# PIC32MK1024GPK100 device description
Architecture: MIPS; Family: PIC32MK; Series: PIC32MK
Registers are 32-bit, read-write, no defined reset value unless marked. A register's access mark holds for its fields unless they carry their own. Offsets are from the block's base; [hi:lo] are bit positions; {n}, {i} and the like mark numbered series; 'fields as' and 'values as' point back to an identical list.

## USB
Instances: USB 0x1f889040 in periph_pb5_std
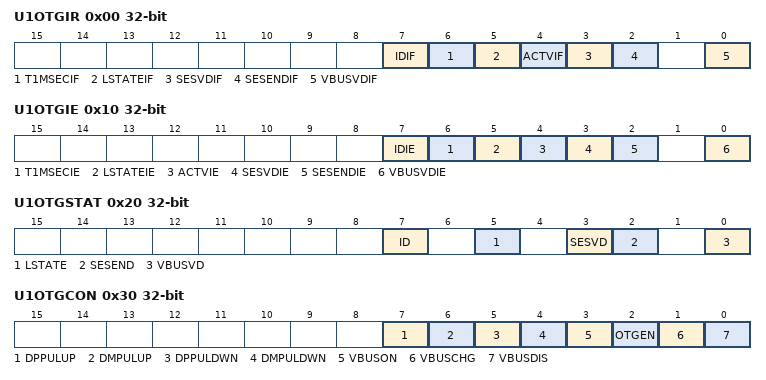
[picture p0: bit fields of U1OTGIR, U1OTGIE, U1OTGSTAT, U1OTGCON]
0x00 U1OTGIR — USB OTG Interrupt Status Register (x = 1 and 2)
  [7] IDIF — ID State Change Indicator bit
    1=Change in ID state is detected; 0=No change in ID state is detected
  [6] T1MSECIF — 1 Millisecond Timer bit
    1=1 millisecond timer has expired; 0=1 millisecond timer has not expired
  [5] LSTATEIF — Line State Stable Indicator bit
    1=USB line state has been stable for 1 millisecond; 0=USB line state has not been stable for 1 millisecond
  [4] ACTVIF — Bus Activity Indicator bit
    1=Activity on the D+, D-, ID or VBUS pins has caused the device to wake-up; 0=Activity has not been detected
  [3] SESVDIF — Session Valid Change Indicator bit
    1=Vbus voltage has dropped below the session end level; 0=Vbus voltage has not dropped below the session end level
  [2] SESENDIF — B-Device VBUS Change Indicator bit
    1=A change on the session end input was detected; 0=No change on the session end input was detected
  [0] VBUSVDIF — A-Device VBUS Change Indicator bit
    1=Change on the session valid input is detected; 0=No change on the session valid input is detected
0x10 U1OTGIE — USB OTG Interrupt Enable Register (x = 1 and 2)
  [7] IDIE — ID Interrupt Enable bit
    1=ID interrupt is enabled; 0=ID interrupt is disabled
  [6] T1MSECIE — 1 Millisecond Timer Interrupt Enable bit
    1=1 millisecond timer interrupt is enabled; 0=1 millisecond timer interrupt is disabled
  [5] LSTATEIE — Line State Interrupt Enable bit
    1=Line state interrupt is enabled; 0=Line state interrupt is disabled
  [4] ACTVIE — Bus Activity Interrupt Enable bit
    1=ACTIVITY interrupt is enabled; 0=ACTIVITY interrupt is disabled
  [3] SESVDIE — Session Valid Interrupt Enable bit
    1=Session valid interrupt is enabled; 0=Session valid interrupt is disabled
  [2] SESENDIE — B-Session End Interrupt Enable bit
    1=B-session end interrupt is enabled; 0=B-session end interrupt is disabled
  [0] VBUSVDIE — A- Vbus Valid Interrupt Enable bit
    1=A-Vbus valid interrupt is enabled; 0=A-Vbus valid interrupt is disabled
0x20 U1OTGSTAT — USB OTG Status Register (x = 1 and 2)
  [7] ID — ID Pin State Indicator bit
    1=No cable is attached or a Type-B cable has been plugged into the USB receptacle; 0=A Type-A cable has been plugged into the USB receptacle
  [5] LSTATE — Line State Stable Indicator bit
    1=USB line state (SE0 (UxCON) and JSTATE) has been stable for the previous 1 ms; 0=USB line state (SE0 and JSTATE) has not been stable for the previous 1 ms
  [3] SESVD — Session Valid Indicator bit
    1=Vbus voltage is above Session Valid on the A or B device; 0=Vbus voltage is below Session Valid on the A or B device
  [2] SESEND — B-Device Session End Indicator bit
    1=Vbus voltage is below Session Valid on the B device; 0=Vbus voltage is above Session Valid on the B device
  [0] VBUSVD — A-Device Vbus Valid Indicator bit
    1=Vbus voltage is above Session Valid on the A device; 0=Vbus voltage is below Session Valid on the A device
0x30 U1OTGCON — USB OTG Control Register (x = 1 and 2)
  [7] DPPULUP — D+ Pull-Up Enable bit
    1=D+ data line pull-up resistor is enabled; 0=D+ data line pull-up resistor is disabled
  [6] DMPULUP — D- Pull-Up Enable bit
    1=D- data line pull-up resistor is enabled; 0=D- data line pull-up resistor is disabled
  [5] DPPULDWN — D+ Pull-Down Enable bit
    1=D+ data line pull-down resistor is enabled; 0=D+ data line pull-down resistor is disabled
  [4] DMPULDWN — D- Pull-Down Enable bit
    1=D- data line pull-down resistor is enabled; 0=D- data line pull-down resistor is disabled
  [3] VBUSON — Vbus Power-on bit
    1=Vbus line is powered; 0=Vbus line is not powered
  [2] OTGEN — OTG Functionality Enable bit
    1=DPPULUP, DMPULUP, DPPULDWN and DMPULDWN bits are under software control; 0=DPPULUP, DMPULUP, DPPULDWN and DMPULDWN bits are under USB hardware control
  [1] VBUSCHG — Vbus Charge Enable bit
    1=Vbus line is charged through a pull-up resistor; 0=Vbus line is not charged through a resistor
  [0] VBUSDIS — Vbus Discharge Enable bit
    1=Vbus line is discharged through a pull-down resistor; 0=Vbus line is not discharged through a resistor
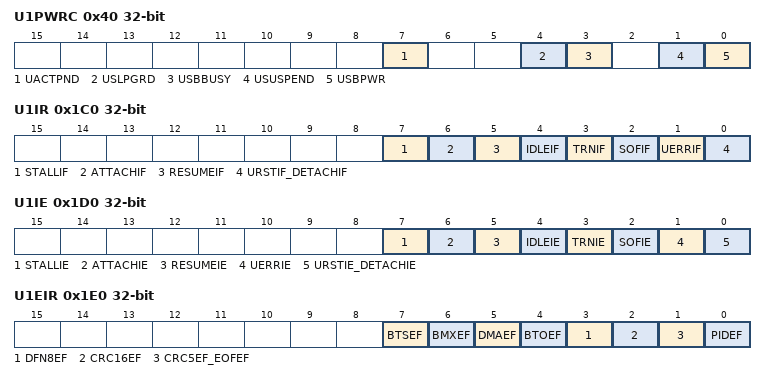
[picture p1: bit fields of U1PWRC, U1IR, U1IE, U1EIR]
0x40 U1PWRC — USB Power Control Register (x = 1 and 2)
  [7] UACTPND — USB Activity Pending bit
    1=USB hardware has detected a change in link status; however; 0=An interrupt is not pending
  [4] USLPGRD — USB Sleep Entry Guard bit
    1=Sleep entry is blocked if USB bus activity is detected or if a notification is pending; 0=USB module does not block Sleep entry
  [3] USBBUSY — USB Module Busy bit
    1=USB module is active or disabled; 0=USB module is not active and is ready to be enabled
  [1] USUSPEND — USB Suspend Mode bit
    1=USB module is placed in Suspend mode (The 48 MHz USB clock will be gated off. The transceiver is placed in a low-power state.); 0=USB module operates normally
  [0] USBPWR — USB Operation Enable bit
    1=USB module is turned on; 0=USB module is disabled (Outputs held inactive
0x1C0 U1IR — USB Interrupt Register (x = 1 and 2)
  [7] STALLIF — STALL Handshake Interrupt bit
    1=(In Host mode)a STALL handshake was received during the handshake phase of the transaction / (In Device mode)a STALL handshake was transmitted during the handshake phase of the transaction; 0=STALL handshake has not been sent
  [6] ATTACHIF — Peripheral Attach Interrupt bit
    1=Peripheral attachment was detected by the USB module; 0=Peripheral attachment was not detected
  [5] RESUMEIF — Resume Interrupt bit
    1=K-State is observed on the D+ or D- pin for 2.5 s; 0=K-State is not observed
  [4] IDLEIF — Idle Detect Interrupt bit
    1=Idle condition detected (constant Idle state of 3 ms or more); 0=No Idle condition detected
  [3] TRNIF — Token Processing Complete Interrupt bit
    1=Processing of current token is complete; a read of the UxSTAT register will provide endpoint information; 0=Processing of current token not complete
  [2] SOFIF — SOF Token Interrupt bit
    1=SOF token received by the peripheral or the SOF threshold reached by the host; 0=SOF token was not received nor threshold reached
  [1] UERRIF — USB Error Condition Interrupt bit
    1=Unmasked error condition has occurred; 0=Unmasked error condition has not occurred
  [0] URSTIF_DETACHIF — (Device mode) USB Reset Interrupt bit Device mode / (Host mode)USB Detach Interrupt bit Host mode
    1=(Device mode)Valid USB Reset has occurred / (Host mode)Peripheral detachment was detected by the USB module; 0=(Device mode)No USB Reset has occurred / (Host mode)Peripheral detachment was not detected
0x1D0 U1IE — USB Interrupt Enable Register (x = 1 and 2)
  [7] STALLIE — STALL Handshake Interrupt Enable bit
    1=STALL interrupt is enabled; 0=STALL interrupt is disabled
  [6] ATTACHIE — ATTACH Interrupt Enable bit
    1=ATTACH interrupt is enabled; 0=ATTACH interrupt is disabled
  [5] RESUMEIE — RESUME Interrupt Enable bit
    1=RESUME interrupt is enabled; 0=RESUME interrupt is disabled
  [4] IDLEIE — Idle Detect Interrupt Enable bit
    1=Idle interrupt is enabled; 0=Idle interrupt is disabled
  [3] TRNIE — Token Processing Complete Interrupt Enable bit
    1=TRNIF interrupt is enabled; 0=TRNIF interrupt is disabled
  [2] SOFIE — SOF Token Interrupt Enable bit
    1=SOFIF interrupt is enabled; 0=SOFIF interrupt is disabled
  [1] UERRIE — USB Error Interrupt Enable bit
    1=USB Error interrupt is enabled; 0=USB Error interrupt is disabled
  [0] URSTIE_DETACHIE — (Device mode) USB Reset Interrupt Enable bit Device mode / (Host mode)USB Detach Interrupt Enable bit Host Mode
    1=(Device mode) URSTIF interrupt is enabled / (Host mode) DATTCHIF interrupt is enabled; 0=(Device mode) URSTIF interrupt is disabled / (Host mode) DATTCHIF interrupt is disabled
0x1E0 U1EIR — USB Error Interrupt Status Register (x = 1 and 2)
  [7] BTSEF — Bit Stuff Error Flag bit
    1=Packet rejected due to bit stuff error; 0=Packet accepted
  [6] BMXEF — Bus Matrix Error Flag bit
    1=The base address, of the BDT, or the address of an individual buffer pointed to by a BDT entry, is invalid; 0=No address error
  [5] DMAEF — DMA Error Flag bit
    1=USB DMA error condition detected; 0=No DMA error
  [4] BTOEF — Bus Turnaround Time-Out Error Flag bit
    1=Bus turnaround time-out has occurred; 0=No bus turnaround time-out
  [3] DFN8EF — Data Field Size Error Flag bit
    1=Data field received is not an integral number of bytes; 0=Data field received is an integral number of bytes
  [2] CRC16EF — CRC16 Failure Flag bit
    1=Data packet rejected due to CRC16 error; 0=Data packet accepted
  [1] CRC5EF_EOFEF — (Device mode)CRC5 Host Error Flag bit / (Host mode)EOF Error Flag bit
    1=(Device mode)Token packet rejected due to CRC5 error / (Host mode)EOF error condition detected; 0=(Device mode)Token packet accepted / (Host mode)No EOF error condition
  [0] PIDEF — PID Check Failure Flag bit
    1=PID check failed; 0=PID check passed
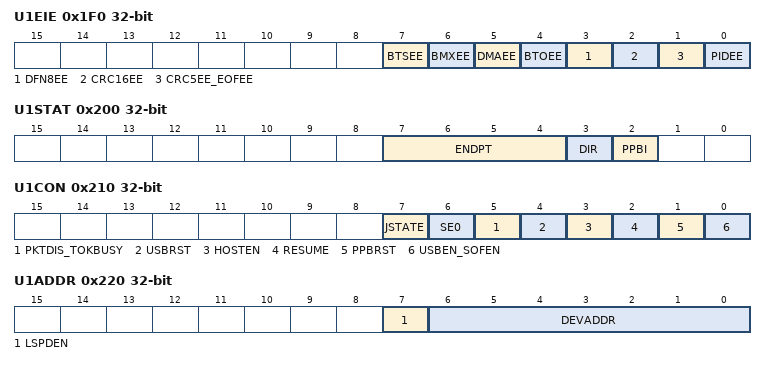
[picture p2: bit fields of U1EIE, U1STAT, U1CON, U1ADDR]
0x1F0 U1EIE — USB Error Interrupt Enable Register (x = 1 and 2)
  [7] BTSEE — Bit Stuff Error Interrupt Enable bit
    1=BTSEF interrupt is enabled; 0=BTSEF interrupt is disabled
  [6] BMXEE — Bus Matrix Error Interrupt Enable bit
    1=BMXEF interrupt is enabled; 0=BMXEF interrupt is disabled
  [5] DMAEE — DMA Error Interrupt Enable bit
    1=DMAEF interrupt is enabled; 0=DMAEF interrupt is disabled
  [4] BTOEE — Bus Turnaround Time-out Error Interrupt Enable bit
    1=BTOEF interrupt is enabled; 0=BTOEF interrupt is disabled
  [3] DFN8EE — Data Field Size Error Interrupt Enable bit
    1=DFN8EF interrupt is enabled; 0=DFN8EF interrupt is disabled
  [2] CRC16EE — CRC16 Failure Interrupt Enable bit
    1=CRC16EF interrupt is enabled; 0=CRC16EF interrupt is disabled
  [1] CRC5EE_EOFEE — (Device mode) CRC5 Host Error Interrupt Enable bit / (Host mode) EOF Error Interrupt Enable bit
    1=(Device mode)CRC5EF interrupt is enabled / (Host mode)EOF interrupt is enabled; 0=(Device mode)CRC5EF interrupt is disabled / (Host mode)EOF interrupt is disabled
  [0] PIDEE — PID Check Failure Interrupt Enable bit
    1=PIDEF interrupt is enabled; 0=PIDEF interrupt is disabled
0x200 U1STAT ro — USB Status Register (x = 1 and 2)
  [7:4] ENDPT — Encoded Number of Last Endpoint Activity bits
    {v}=Endpoint {v} (v=0..15)
  [3] DIR — Last BD Direction Indicator bit
    1=Last transaction was a transmit transfer (TX); 0=Last transaction was a receive transfer (RX)
  [2] PPBI — Ping-Pong BD Pointer Indicator bit
    1=The last transaction was to the ODD BD bank; 0=The last transaction was to the EVEN BD bank
0x210 U1CON — USB Control Register (x = 1 and 2)
  [7] JSTATE — Live Differential Receiver JSTATE flag bit
    1=JSTATE detected on the USB; 0=No JSTATE detected
  [6] SE0 — Live Single-Ended Zero flag bit
    1=Single Ended Zero detected on the USB; 0=No Single Ended Zero detected
  [5] PKTDIS_TOKBUSY — (Device mode) Packet Transfer Disable bit / (Host mode) Token Busy Indicator bit
    1=(Device mode)Token and packet processing disabled (set upon SETUP token received) / (Host mode)Token being executed by the USB module; 0=(Device mode)Token and packet processing enabled / (Host mode)No token being executed
  [4] USBRST — Module Reset bit
    1=USB reset is generated; 0=USB reset is terminated
  [3] HOSTEN — Host Mode Enable bit
    1=USB host capability is enabled; 0=USB host capability is disabled
  [2] RESUME — RESUME Signaling Enable bit
    1=RESUME signaling is activated; 0=RESUME signaling is disabled
  [1] PPBRST — Ping-Pong Buffers Reset bit
    1=Reset all Even/Odd buffer pointers to the EVEN BD banks; 0=Even/Odd buffer pointers not being Reset
  [0] USBEN_SOFEN — (Device mode)USB Module Enable bit / (Host mode)
    1=(Device mode)USB module and supporting circuitry is enabled / (Host mode)SOF token sent every 1 ms; 0=(Device mode)USB module and supporting circuitry is disabled / (Host mode)SOF token disabled
0x220 U1ADDR — USB Address Register (x = 1 and 2)
  [7] LSPDEN — Low Speed Enable Indicator bit
    1=Next token command to be executed at Low Speed; 0=Next token command to be executed at Full Speed
  [6:0] DEVADDR
0x230 U1BDTP1 — USB BDT Page 1 Register (x = 1 and 2)
  [7:1] BDTPTRL
0x240 U1FRML ro — USB Frame Number Low Register (x = 1 and 2)
  [7:0] FRML
0x250 U1FRMH ro — USB Frame Number High Register (x = 1 and 2)
  [2:0] FRMH
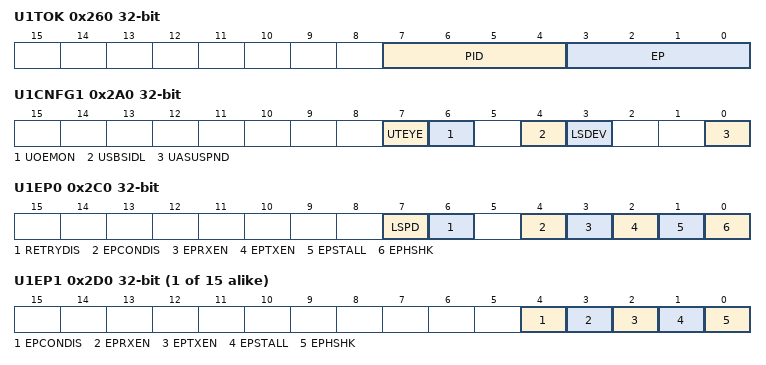
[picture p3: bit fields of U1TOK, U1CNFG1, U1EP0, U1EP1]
0x260 U1TOK — USB Token Register (x = 1 and 2)
  [7:4] PID — Token Type Indicator bits
    1=OUT (TX) token type transaction; 9=IN (RX) token type transaction; 13=SETUP (TX) token type transaction
  [3:0] EP
0x270 U1SOF — USB SOF Threshold Register (x = 1 and 2)
  [7:0] CNT — SOF Threshold Value bits
    74=64-byte packet; 42=32-byte packet; 26=16-byte packet; 18=8-byte packet
0x280 U1BDTP2 — USB BDT PAGE 2 Register (x = 1 and 2)
  [7:0] BDTPTRH
0x290 U1BDTP3 — USB BDT PAGE 3 Register (x = 1 and 2)
  [7:0] BDTPTRU
0x2A0 U1CNFG1 — USB Configuration 1 Register (x = 1 and 2)
  [7] UTEYE — USB Eye-Pattern Test Enable bit
    1=Eye-Pattern Test is enabled; 0=Eye-Pattern Test is disabled
  [6] UOEMON — USB
    1=OE signal is active; it indicates intervals during which the D+/D- lines are driving; 0=OE signal is inactive
  [4] USBSIDL — Stop in Idle Mode bit
    1=Discontinue module operation when device enters Idle mode; 0=Continue module operation in Idle mode
  [3] LSDEV — Low-Speed Device Enable bit
    1=USB module to operate in Low-Speed Device mode; 0=USB module to operate in OTG
  [0] UASUSPND — Automatic Suspend Enable bit
    1=USB module automatically suspends upon entry to Sleep mode. See the USUSPEND bit (UxPWRC) in; 0=USB module does not automatically suspend upon entry to Sleep mode. Software must use the USUSPEND bit (UxPWRC) to suspend the module
0x2C0 U1EP0 — USB Endpoint Control Register 0
  [7] LSPD — Low-Speed Direct Connection Enable bit
    1=Direct connection to a low-speed device is enabled; 0=Direct connection to a low-speed device is disabled; hub required with PRE_PID
  [6] RETRYDIS — Retry Disable bit
    1=Retry NAKed transactions is disabled; 0=Retry NAKed transactions is enabled; retry done in hardware
  [4] EPCONDIS — Bidirectional Endpoint Control bit
    1=(If EPTXEN is 1 and EPRXEN is 1)Disable Endpoint n from Control transfers; only TX and RX transfers allowed / (else)bit is ignored; 0=(If EPTXEN is 1 and EPRXEN is 1)Enable Endpoint n for Control (SETUP) transfers; TX and RX transfers also allowed / (else)bit is ignored
  [3] EPRXEN — Endpoint Receive Enable bit
    1=Endpoint n receive is enabled; 0=Endpoint n receive is disabled
  [2] EPTXEN — Endpoint Transmit Enable bit
    1=Endpoint n transmit is enabled; 0=Endpoint n transmit is disabled
  [1] EPSTALL — Endpoint Stall Status bit
    1=Endpoint n was stalled; 0=Endpoint n was not stalled
  [0] EPHSHK — Endpoint Handshake Enable bit
    1=Endpoint Handshake is enabled; 0=Endpoint Handshake is disabled (typically used for isochronous endpoints)
{0x2C0+0x10*i} U1EP{i} (i=1..15) — USB Endpoint Control Register {i}
  [4] EPCONDIS — Bidirectional Endpoint Control bit
    values as U1EP0.EPCONDIS
  [3] EPRXEN — Endpoint Receive Enable bit
    values as U1EP0.EPRXEN
  [2] EPTXEN — Endpoint Transmit Enable bit
    values as U1EP0.EPTXEN
  [1] EPSTALL — Endpoint Stall Status bit
    1=Endpoint n was stalled; 0=Endpoint n was not stalled
  [0] EPHSHK — Endpoint Handshake Enable bit
    values as U1EP0.EPHSHK
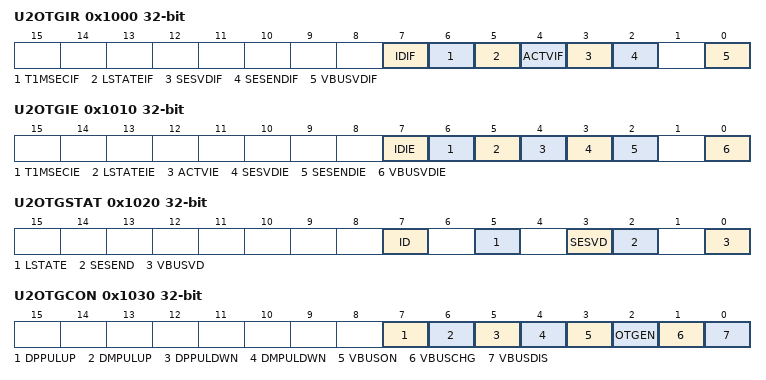
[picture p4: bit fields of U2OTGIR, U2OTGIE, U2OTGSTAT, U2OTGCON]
0x1000 U2OTGIR — USB OTG Interrupt Status Register (x = 1 and 2)
  fields as U1OTGIR
0x1010 U2OTGIE — USB OTG Interrupt Enable Register (x = 1 and 2)
  fields as U1OTGIE
0x1020 U2OTGSTAT — USB OTG Status Register (x = 1 and 2)
  fields as U1OTGSTAT
0x1030 U2OTGCON — USB OTG Control Register (x = 1 and 2)
  fields as U1OTGCON
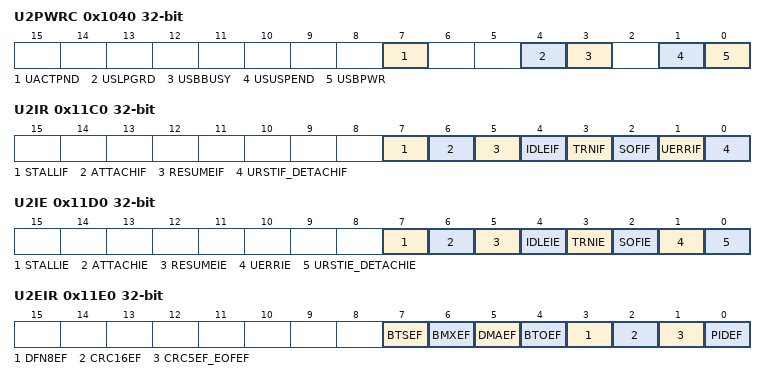
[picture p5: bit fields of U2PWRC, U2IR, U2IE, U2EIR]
0x1040 U2PWRC — USB Power Control Register (x = 1 and 2)
  fields as U1PWRC
0x11C0 U2IR — USB Interrupt Register (x = 1 and 2)
  fields as U1IR
0x11D0 U2IE — USB Interrupt Enable Register (x = 1 and 2)
  fields as U1IE
0x11E0 U2EIR — USB Error Interrupt Status Register (x = 1 and 2)
  fields as U1EIR
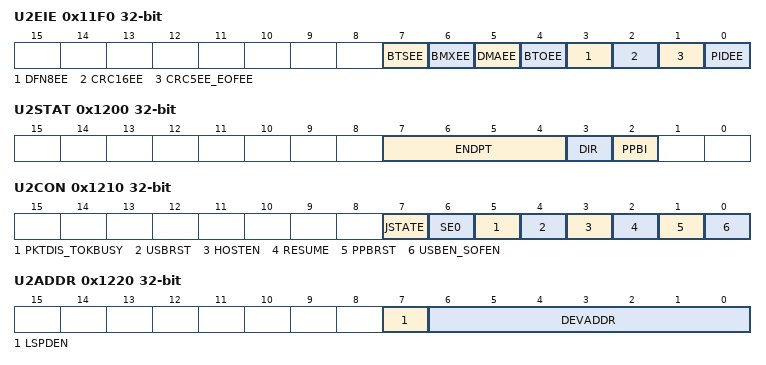
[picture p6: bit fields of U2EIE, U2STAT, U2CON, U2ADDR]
0x11F0 U2EIE — USB Error Interrupt Enable Register (x = 1 and 2)
  fields as U1EIE
0x1200 U2STAT ro — USB Status Register (x = 1 and 2)
  fields as U1STAT
0x1210 U2CON — USB Control Register (x = 1 and 2)
  fields as U1CON
0x1220 U2ADDR — USB Address Register (x = 1 and 2)
  fields as U1ADDR
0x1230 U2BDTP1 — USB BDT Page 1 Register (x = 1 and 2)
  [7:1] BDTPTRL
0x1240 U2FRML ro — USB Frame Number Low Register (x = 1 and 2)
  [7:0] FRML
0x1250 U2FRMH ro — USB Frame Number High Register (x = 1 and 2)
  [2:0] FRMH
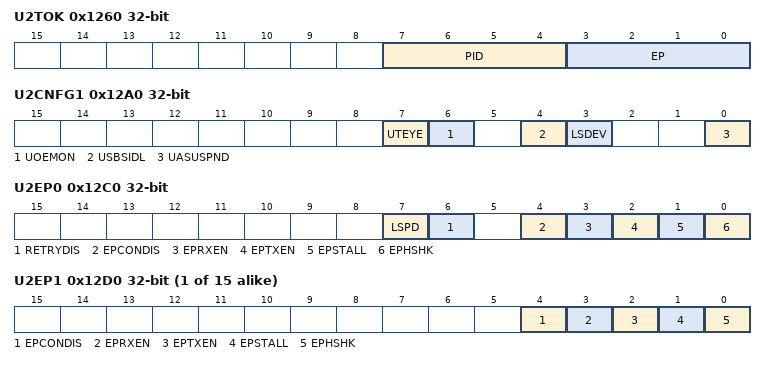
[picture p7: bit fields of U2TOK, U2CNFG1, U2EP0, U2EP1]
0x1260 U2TOK — USB Token Register (x = 1 and 2)
  fields as U1TOK
0x1270 U2SOF — USB SOF Threshold Register (x = 1 and 2)
  fields as U1SOF
0x1280 U2BDTP2 — USB BDT PAGE 2 Register (x = 1 and 2)
  [7:0] BDTPTRH
0x1290 U2BDTP3 — USB BDT PAGE 3 Register (x = 1 and 2)
  [7:0] BDTPTRU
0x12A0 U2CNFG1 — USB Configuration 1 Register (x = 1 and 2)
  fields as U1CNFG1
0x12C0 U2EP0 — USB Endpoint Control Register 0
  fields as U1EP0
{0x12C0+0x10*i} U2EP{i} (i=1..15) — USB Endpoint Control Register {i}
  fields as U1EP1
